# LPC12D27 register map
File version: 3
Registers are 32-bit, read-write, reset 0x0 unless marked. A register's access mark holds for its fields unless they carry their own. Offsets are from the block's base; [hi:lo] are bit positions; {n}, {i} and the like mark numbered series.

## MICRO_DMA — Product name title=UM10441 Chapter title=LPC122x General purpose micro DMA controller Modification date=2/10/2011 Major revision=0 Minor revision=17
Base 0x4004C000
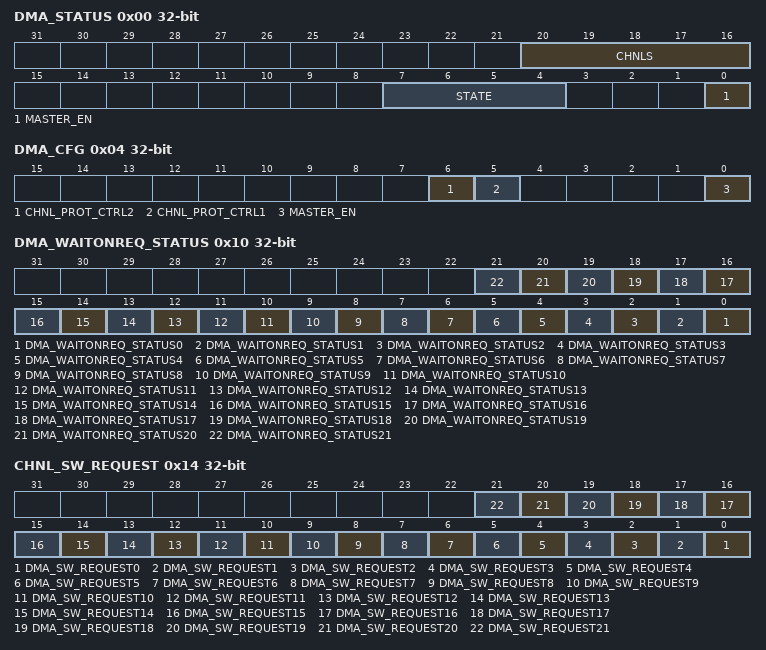
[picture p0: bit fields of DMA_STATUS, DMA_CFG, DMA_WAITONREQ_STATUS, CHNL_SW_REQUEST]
0x00 DMA_STATUS ro
  [20:16] CHNLS — The LPC122x micro DMA controller is configured for 21 channels. Reset value is number of channels - 1.
  [7:4] STATE — Current state of the control state machine. State can be one of the following: 0000 = idle 0001 = reading channel controller data 0010 = reading source data end pointer 0011 = reading destination data end pointer 0100 = reading source data 0101 = writing destination data 0110 = waiting for DMA request to clear 0111 = writing channel controller data 1000 = stalled 1001 = done 1010 = peripheral scatter-gather transition 1011-1111 = undefined
  [0] MASTER_EN — Enable status of the controller: 0 = controller disabled. 1 = controller enabled.
0x04 DMA_CFG wo — DMA configuration register
  [6] CHNL_PROT_CTRL2 — Channel protection buffer control:
    0=NON_BUFFERABLE; 1=BUFFERABLE
  [5] CHNL_PROT_CTRL1 — Channel protection access control:
    0=USER_ACCESS; 1=PRIVILEGED_ACCESS
  [0] MASTER_EN — Enable for the controller:
    0=DISABLES_THE_CONTROL (Disables the controller.); 1=ENABLES_THE_CONTROLL (Enables the controller.)
0x08 CTRL_BASE_PTR — Channel control base pointer register
  [31:8] CTRL_BASE_PTR — Pointer to the base address of the primary data structure.
0x0C ATL_CTRL_BASE_PTR ro — Channel alternate control base pointer register
  [31:0] ALT_CTRL_BASE_PTR — Base address of the alternate data structure
0x10 DMA_WAITONREQ_STATUS ro — Channel wait on request status register
  [n] DMA_WAITONREQ_STATUS{n} (n=0..21) — Channel c wait-on-request status (c = 0 to 20): Bit c = 0: dma_waitonreq[c] is LOW. Bit c = 1: dma_waitonreq[c] is HIGH.
0x14 CHNL_SW_REQUEST wo — Channel software request register
  [n] DMA_SW_REQUEST{n} (n=0..21) — Set the appropriate bit to generate a software DMA request on the corresponding DMA channel. Write as: Bit [c] = 0: Does not create a DMA request for channel c. Bit [c] = 1: Creates a DMA request for channel c.
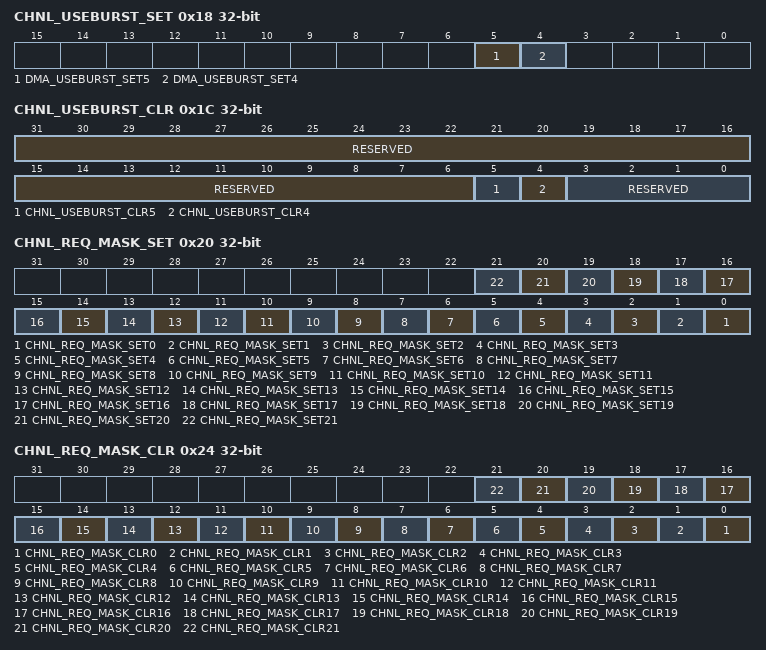
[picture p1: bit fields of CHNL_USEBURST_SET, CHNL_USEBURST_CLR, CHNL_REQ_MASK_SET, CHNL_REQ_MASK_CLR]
0x18 CHNL_USEBURST_SET — Channel useburst set register
  [5] DMA_USEBURST_SET5 — Returns the useburst status for channel c (c = 0 to 20) or disables dma_sreq[c] from generating DMA requests. (For channels 4 and 5 only.) Read as: Bit [c] = 0: DMA channel c responds to requests that it receives on dma_req[c] or dma_sreq[c]. The controller performs 2R, or single, bus transfers. Bit [c] = 1: DMA channel c does not respond to requests that it receives on dma_sreq[c]. The controller only responds to dma_req[c] requests and performs 2R transfers. Write as: Bit [c] = 0: No effect. Use the CHNL_USEBURST_CLR register to set bit [c] to 0. Bit [c] = 1: Disables dma_sreq[C] from generating DMA requests. The controller performs 2R transfers.
  [4] DMA_USEBURST_SET4 — Returns the useburst status for channel c (c = 0 to 20) or disables dma_sreq[c] from generating DMA requests. (For channels 4 and 5 only.) Read as: Bit [c] = 0: DMA channel c responds to requests that it receives on dma_req[c] or dma_sreq[c]. The controller performs 2R, or single, bus transfers. Bit [c] = 1: DMA channel c does not respond to requests that it receives on dma_sreq[c]. The controller only responds to dma_req[c] requests and performs 2R transfers. Write as: Bit [c] = 0: No effect. Use the CHNL_USEBURST_CLR register to set bit [c] to 0. Bit [c] = 1: Disables dma_sreq[C] from generating DMA requests. The controller performs 2R transfers.
0x1C CHNL_USEBURST_CLR wo — Channel useburst clear register
  [31:6] RESERVED — Set the appropriate bit to enable dma_sreq[c] to generate requests. (For channels 4 and 5 only.) Write as: Bit [c] = 0: No effect. Use the chnl_useburst_set Register to disable dma_sreq[c] from generating requests. Bit [c] = 1: Enables dma_sreq[c] to generate DMA requests.
  [5] CHNL_USEBURST_CLR5 — Set the appropriate bit to enable dma_sreq[c] to generate requests. (For channels 4 and 5 only.) Write as: Bit [c] = 0: No effect. Use the chnl_useburst_set Register to disable dma_sreq[c] from generating requests. Bit [c] = 1: Enables dma_sreq[c] to generate DMA requests.
  [4] CHNL_USEBURST_CLR4 — Set the appropriate bit to enable dma_sreq[c] to generate requests. (For channels 4 and 5 only.) Write as: Bit [c] = 0: No effect. Use the chnl_useburst_set Register to disable dma_sreq[c] from generating requests. Bit [c] = 1: Enables dma_sreq[c] to generate DMA requests.
  [3:0] RESERVED — Set the appropriate bit to enable dma_sreq[c] to generate requests. (For channels 4 and 5 only.) Write as: Bit [c] = 0: No effect. Use the chnl_useburst_set Register to disable dma_sreq[c] from generating requests. Bit [c] = 1: Enables dma_sreq[c] to generate DMA requests.
0x20 CHNL_REQ_MASK_SET — Channel request mask set register
  [n] CHNL_REQ_MASK_SET{n} (n=0..21) — Returns the request mask status of dma_req[c] and dma_sreq[c], or disables the corresponding channel from generating DMA requests. Read as: Bit [c] = 0: External requests are enabled for channel c. Bit [c] = 1: External requests are disabled for channel c. Write as: Bit [c] = 0: No effect. Use the CHNL_REQ_MASK_CLR Register to enable DMA requests. Bit [c] = 1: Disables dma_req[c] and dma_sreq[c] from generating DMA requests.
0x24 CHNL_REQ_MASK_CLR wo — Channel request mask clear register
  [n] CHNL_REQ_MASK_CLR{n} (n=0..21) — Set the appropriate bit to enable DMA requests for the channel corresponding to dma_req[c] and dma_sreq[c]. Write as: Bit [c] = 0: No effect. Use the chnl_req_mask_set Register to disable dma_req[c] and dma_sreq[c] from generating requests. Bit [c] = 1: Enables dma_req[c] or dma_sreq[c] to generate DMA requests.
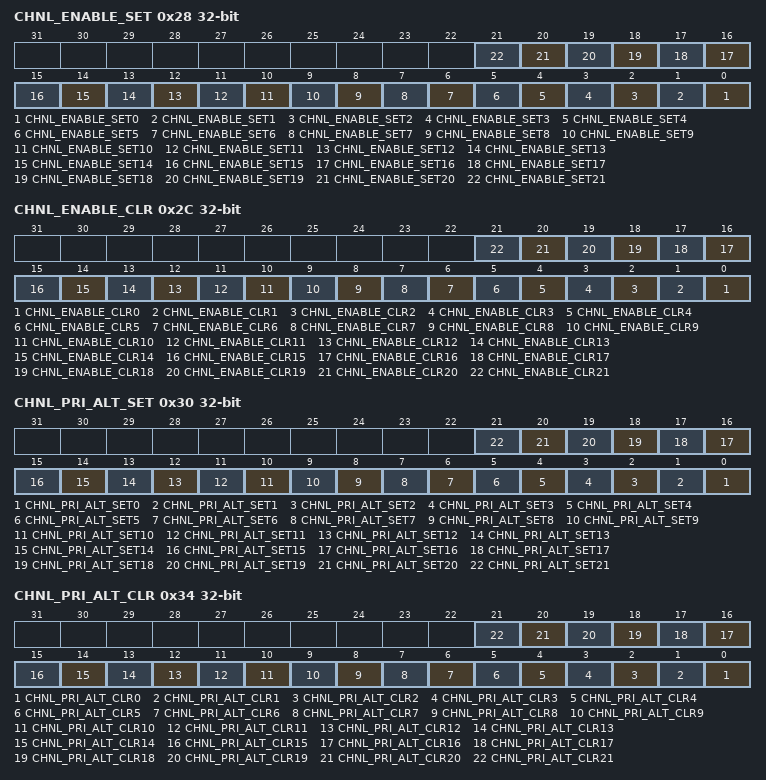
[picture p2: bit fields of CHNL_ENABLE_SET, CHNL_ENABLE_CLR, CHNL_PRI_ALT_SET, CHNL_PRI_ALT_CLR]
0x28 CHNL_ENABLE_SET — Channel enable set register
  [n] CHNL_ENABLE_SET{n} (n=0..21) — Returns the enable status of the channels, or enables the corresponding channels. Read as: Bit [c] = 0: Channel c is disabled. Bit [c] = 1 Channel c is enabled. Write as: Bit [c] = 0: No effect. Use the CHNL_ENABLE_CLR Register to disable a channel. Bit [c] = 1: Enables channel c.
0x2C CHNL_ENABLE_CLR wo — Channel enable clear register
  [n] CHNL_ENABLE_CLR{n} (n=0..21) — Set the appropriate bit to disable the corresponding DMA channel. Write as: Bit [c] = 0: No effect. Use the CHNL_ENABLE_SET Register to enable DMA channels. Bit [c] = 1 Disables channel c.
0x30 CHNL_PRI_ALT_SET — Channel primary-alternate set register
  [n] CHNL_PRI_ALT_SET{n} (n=0..21) — Returns the channel control data structure status, or selects the alternate data structure for the corresponding DMA channel c. Read as: Bit [c] = 0: DMA channel c is using the primary data structure. Bit [c] = 1: DMA channel c is using the alternate data structure. Write as: Bit [c] = 0: No effect. Use the CHNL_PRI_ALT_CLR Register to set bit [c] to 0. Bit [c] = 1: Selects the alternate data structure for channel c.
0x34 CHNL_PRI_ALT_CLR wo — Channel primary-alternate clear register
  [n] CHNL_PRI_ALT_CLR{n} (n=0..21) — Set the appropriate bit to select the primary data structure for the corresponding DMA channel c. Write as: Bit [c] = 0: No effect. Use the CHNL_PRI_ALT_SET Register to select the alternate data structure. Bit [c] = 1: Selects the primary data structure for channel c.
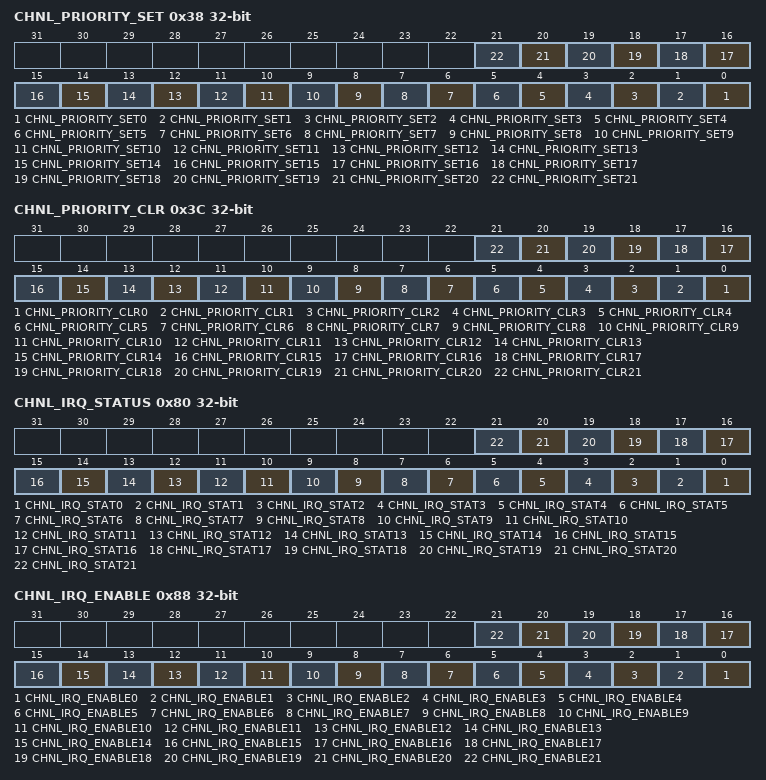
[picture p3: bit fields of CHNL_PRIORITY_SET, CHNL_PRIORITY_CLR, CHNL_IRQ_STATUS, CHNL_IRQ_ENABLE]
0x38 CHNL_PRIORITY_SET — Channel priority set register
  [n] CHNL_PRIORITY_SET{n} (n=0..21) — Returns the channel priority mask status, or sets the channel priority to high. Read as: Bit [c] = 0: DMA channel c is using the default priority level. Bit [c] = 1: DMA channel c is using a high priority level. Write as: Bit [c] = 0: No effect. Use the CHNL_PRIORITY_CLR Register to set channel c to the default priority level. Bit [c] = 1: Channel c uses the high priority level.
0x3C CHNL_PRIORITY_CLR wo — Channel priority clear register
  [n] CHNL_PRIORITY_CLR{n} (n=0..21) — Set the appropriate bit to select the default priority level for the specified DMA channel. Write as: Bit [c] = 0: No effect. Use the CHNL_PRIORITY_SET Register to set channel c to the high priority level. Bit [c] = 1: Channel c uses the default priority level.
0x4C ERR_CLR — Bus error clear register
  [0] ERR_CLR — Returns the status of dma_error or sets the signal LOW. Read as: 0 = dma_err is LOW. 1 = dma_err is HIGH. Write as: 0 = No effect, status of dma_err is unchanged. 1 = Sets dma_err LOW.
0x80 CHNL_IRQ_STATUS — Channel DMA interrupt status register
  [n] CHNL_IRQ_STAT{n} (n=0..21) — Returns the status of the DMA done interrupt for each channel. Read as: Bit [c] = 0: DMA done interrupt not asserted. Bit [c] = 1: DMA transfer complete for Channel c. Write as: Bit [c] = 0: No effect. Bit [c] = 1: Clears the DMA done status for Channel c.
0x84 IRQ_ERR_ENABLE — DMA error interrupt enable register
  [0] IRQ_ERR_ENABLE — Enables the DMA error (dma_error) signal to create an interrupt. Write as: Bit 0 = 0: DMA error interrupt disabled. Bit 0 = 1: DMA error interrupt enabled.
0x88 CHNL_IRQ_ENABLE — Channel DMA interrupt enable register
  [n] CHNL_IRQ_ENABLE{n} (n=0..21) — Enables the DMA done (dma_done[c]) signal to create an interrupt. Write as: Bit[c] = 0: DMA done interrupt disabled for channel c. Bit[c] = 1: DMA done interrupt enabled for channel c.
